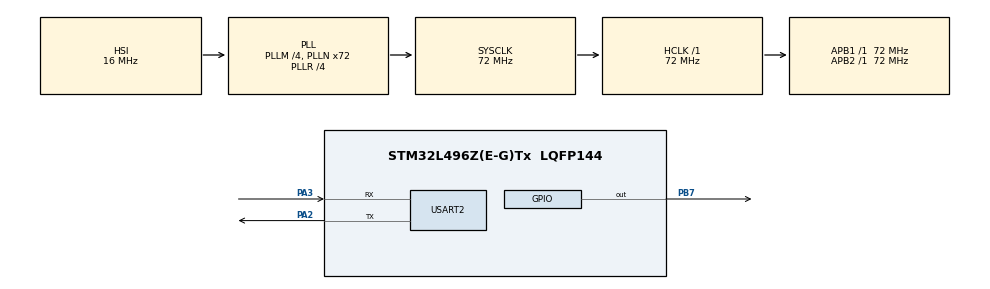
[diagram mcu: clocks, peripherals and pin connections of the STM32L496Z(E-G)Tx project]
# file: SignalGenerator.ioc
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Mcu.Family=STM32L4
Mcu.Name=STM32L496Z(E-G)Tx
Mcu.Package=LQFP144
NVIC.PriorityGroup=NVIC_PRIORITYGROUP_4
NVIC.USART2_IRQn=true\:0\:0\:false\:false\:true\:true\:true
PA2.Mode=Asynchronous
PA2.Signal=USART2_TX
PA3.Mode=Asynchronous
PA3.Signal=USART2_RX
PB7.Signal=GPIO_Output
ProjectManager.HeapSize=0x200
ProjectManager.StackSize=0x400
ProjectManager.TargetToolchain=STM32CubeIDE
RCC.ADCFreq_Value=16000000
RCC.AHBFreq_Value=72000000
RCC.APB1Freq_Value=72000000
RCC.APB1TimFreq_Value=72000000
RCC.APB2Freq_Value=72000000
RCC.APB2TimFreq_Value=72000000
RCC.CortexFreq_Value=72000000
RCC.HCLKFreq_Value=72000000
RCC.HSE_VALUE=8000000
RCC.HSI48_VALUE=48000000
RCC.HSI_VALUE=16000000
RCC.LSE_VALUE=32768
RCC.MSIClockRange=RCC_MSIRANGE_11
RCC.MSI_VALUE=48000000
RCC.PLLM=4
RCC.PLLN=72
RCC.PLLR=RCC_PLLR_DIV4
RCC.PLLSourceVirtual=RCC_PLLSOURCE_HSI
RCC.SYSCLKFreq_VALUE=72000000
RCC.SYSCLKSource=RCC_SYSCLKSOURCE_PLLCLK
RCC.USBFreq_Value=16000000
RCC.VCOOutputFreq_Value=288000000
TIM2.Period=100
TIM2.Prescaler=72-1
TIM2.TIM_MasterOutputTrigger=TIM_TRGO_UPDATE
USART2.VirtualMode-Asynchronous=VM_ASYNC
VP_TIM2_VS_ClockSourceINT.Mode=Internal
board=custom

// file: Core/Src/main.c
/* USER CODE BEGIN Header */
/**
 ******************************************************************************
 * @file           : main.c
 * @brief          : Main program body
 ******************************************************************************
 * @attention
 *
 * <h2><center>&copy; Copyright (c) 2021 STMicroelectronics.
 * All rights reserved.</center></h2>
 *
 * This software component is licensed by ST under BSD 3-Clause license,
 * the "License"; You may not use this file except in compliance with the
 * License. You may obtain a copy of the License at:
 *                        opensource.org/licenses/BSD-3-Clause
 *
 ******************************************************************************
 */
/* USER CODE END Header */
#include "main.h"
#include "tim.h"
#include "usart.h"
#include "gpio.h"

void SystemClock_Config(void);

/* USER CODE BEGIN 0 */
//values of sinewave (or any other waveform)
//could also be generated at the very beginning in STM32 with math function
//here I have externally generated values

#define PI 3.1415926

//void sinwave_calc(int i){
//		sin_val[i] =sin(i*2* PI/100);
//}
char text[] = "hello\n";
void send_string(char *s) {
	HAL_UART_Transmit(&huart2, (uint8_t*) s, strlen(s), 1000);
}
int i = 0;
/* USER CODE END 0 */

int main(void) {

	/* MCU Configuration--------------------------------------------------------*/

	/* Reset of all peripherals, Initializes the Flash interface and the Systick. */
	HAL_Init();

	/* Configure the system clock */
	SystemClock_Config();

	/* Initialize all configured peripherals */
	MX_GPIO_Init();
	MX_TIM2_Init();
	MX_USART2_UART_Init();
	/* USER CODE BEGIN 2 */
	HAL_TIM_Base_Start(&htim2);

	/* USER CODE END 2 */

	/* Infinite loop */
	/* USER CODE BEGIN WHILE */
	while (1) {

		HAL_GPIO_TogglePin(GPIOB, GPIO_PIN_7);
		HAL_Delay(1000);
		/* USER CODE END WHILE */

	}
}

void SystemClock_Config(void) {
	RCC_OscInitTypeDef RCC_OscInitStruct = { 0 };
	RCC_ClkInitTypeDef RCC_ClkInitStruct = { 0 };

	/** Configure the main internal regulator output voltage
	 */
	if (HAL_PWREx_ControlVoltageScaling(PWR_REGULATOR_VOLTAGE_SCALE1)
			!= HAL_OK) {
		Error_Handler();
	}
	/** Initializes the RCC Oscillators according to the specified parameters
	 * in the RCC_OscInitTypeDef structure.
	 */
	RCC_OscInitStruct.OscillatorType = RCC_OSCILLATORTYPE_HSI;
	RCC_OscInitStruct.HSIState = RCC_HSI_ON;
	RCC_OscInitStruct.HSICalibrationValue = RCC_HSICALIBRATION_DEFAULT;
	RCC_OscInitStruct.PLL.PLLState = RCC_PLL_ON;
	RCC_OscInitStruct.PLL.PLLSource = RCC_PLLSOURCE_HSI;
	RCC_OscInitStruct.PLL.PLLM = 4;
	RCC_OscInitStruct.PLL.PLLN = 72;
	RCC_OscInitStruct.PLL.PLLP = RCC_PLLP_DIV2;
	RCC_OscInitStruct.PLL.PLLQ = RCC_PLLQ_DIV2;
	RCC_OscInitStruct.PLL.PLLR = RCC_PLLR_DIV4;
	if (HAL_RCC_OscConfig(&RCC_OscInitStruct) != HAL_OK) {
		Error_Handler();
	}
	/** Initializes the CPU, AHB and APB buses clocks
	 */
	RCC_ClkInitStruct.ClockType = RCC_CLOCKTYPE_HCLK | RCC_CLOCKTYPE_SYSCLK
			| RCC_CLOCKTYPE_PCLK1 | RCC_CLOCKTYPE_PCLK2;
	RCC_ClkInitStruct.SYSCLKSource = RCC_SYSCLKSOURCE_PLLCLK;
	RCC_ClkInitStruct.AHBCLKDivider = RCC_SYSCLK_DIV1;
	RCC_ClkInitStruct.APB1CLKDivider = RCC_HCLK_DIV1;
	RCC_ClkInitStruct.APB2CLKDivider = RCC_HCLK_DIV1;

	if (HAL_RCC_ClockConfig(&RCC_ClkInitStruct, FLASH_LATENCY_4) != HAL_OK) {
		Error_Handler();
	}
}

void Error_Handler(void) {
	__disable_irq();
	while (1) {
	}
}

/************************ (C) COPYRIGHT STMicroelectronics *****END OF FILE****/
